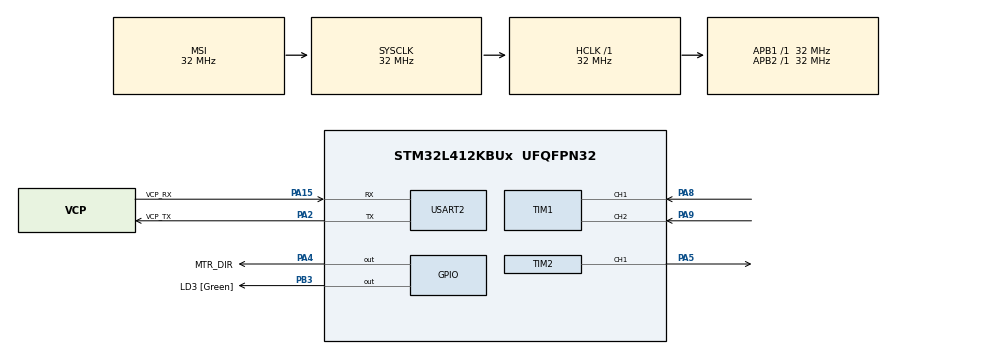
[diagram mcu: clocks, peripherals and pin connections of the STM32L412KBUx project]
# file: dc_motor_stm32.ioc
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Mcu.Family=STM32L4
Mcu.Name=STM32L412KBUx
Mcu.Package=UFQFPN32
NVIC.PriorityGroup=NVIC_PRIORITYGROUP_4
NVIC.TIM1_CC_IRQn=true\:0\:0\:false\:false\:true\:true\:true\:true
PA0-CK_IN.Mode=HSE-External-Clock-Source-for-LittleOrca
PA0-CK_IN.Signal=RCC_CK_IN
PA13\ (JTMS/SWDIO).GPIO_Label=SWDIO
PA13\ (JTMS/SWDIO).Mode=Serial_Wire
PA13\ (JTMS/SWDIO).Signal=SYS_JTMS-SWDIO
PA14\ (JTCK/SWCLK).GPIO_Label=SWCLK
PA14\ (JTCK/SWCLK).Mode=Serial_Wire
PA14\ (JTCK/SWCLK).Signal=SYS_JTCK-SWCLK
PA15\ (JTDI).GPIO_Label=VCP_RX
PA15\ (JTDI).Mode=Asynchronous
PA15\ (JTDI).Signal=USART2_RX
PA2.GPIO_Label=VCP_TX
PA2.Mode=Asynchronous
PA2.Signal=USART2_TX
PA4.GPIO_Label=MTR_DIR
PA4.GPIO_PuPd=GPIO_PULLUP
PA4.Signal=GPIO_Output
PA5.GPIO_PuPd=GPIO_PULLUP
PA5.Signal=S_TIM2_CH1
PA8.GPIO_PuPd=GPIO_PULLUP
PA8.Signal=S_TIM1_CH1
PA9.GPIO_PuPd=GPIO_PULLUP
PA9.Signal=S_TIM1_CH2
PB3\ (JTDO/TRACESWO).GPIO_Label=LD3 [Green]
PB3\ (JTDO/TRACESWO).Signal=GPIO_Output
PC14-OSC32_IN\ (PC14).Mode=LSE-External-Oscillator
PC14-OSC32_IN\ (PC14).Signal=RCC_OSC32_IN
PC15-OSC32_OUT\ (PC15).Mode=LSE-External-Oscillator
PC15-OSC32_OUT\ (PC15).Signal=RCC_OSC32_OUT
ProjectManager.HeapSize=0x200
ProjectManager.StackSize=0x400
ProjectManager.TargetToolchain=STM32CubeIDE
RCC.ADCFreq_Value=32000000
RCC.AHBFreq_Value=32000000
RCC.APB1Freq_Value=32000000
RCC.APB1TimFreq_Value=32000000
RCC.APB2Freq_Value=32000000
RCC.APB2TimFreq_Value=32000000
RCC.CortexFreq_Value=32000000
RCC.FLatency=FLASH_LATENCY_1
RCC.HCLKFreq_Value=32000000
RCC.HSE_VALUE=8000000
RCC.HSI48_VALUE=48000000
RCC.HSICalibrationValue=64
RCC.HSI_VALUE=16000000
RCC.LSE_Drive_Capability=RCC_LSEDRIVE_LOW
RCC.MSIClockRange=RCC_MSIRANGE_10
RCC.MSI_VALUE=32000000
RCC.SYSCLKFreq_VALUE=32000000
RCC.USBFreq_Value=32000000
RCC.VCOOutputFreq_Value=256000000
SH.S_TIM1_CH1.0=TIM1_CH1,Encoder_Interface
SH.S_TIM1_CH2.0=TIM1_CH2,Encoder_Interface
SH.S_TIM2_CH1.0=TIM2_CH1,PWM Generation1 CH1
TIM1.AutoReloadPreload=TIM_AUTORELOAD_PRELOAD_DISABLE
TIM1.EncoderMode=TIM_ENCODERMODE_TI1
TIM2.AutoReloadPreload=TIM_AUTORELOAD_PRELOAD_ENABLE
TIM2.Channel-PWM\ Generation1\ CH1=TIM_CHANNEL_1
USART2.VirtualMode-Asynchronous=VM_ASYNC
board=NUCLEO-L412KB

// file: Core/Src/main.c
/* USER CODE BEGIN Header */
/**
  ******************************************************************************
  * @file           : main.c
  * @brief          : Main program body
  ******************************************************************************
  * @attention
  *
  * Copyright (c) 2024 STMicroelectronics.
  * All rights reserved.
  *
  * This software is licensed under terms that can be found in the LICENSE file
  * in the root directory of this software component.
  * If no LICENSE file comes with this software, it is provided AS-IS.
  *
  ******************************************************************************
  */
/* USER CODE END Header */
#include "main.h"

/* USER CODE BEGIN Includes */
#include "dc_motor.h"
#include "quadrature_encoder_stm32.h"
/* USER CODE END Includes */

TIM_HandleTypeDef htim1;
TIM_HandleTypeDef htim2;

UART_HandleTypeDef huart2;

void SystemClock_Config(void);
static void MX_GPIO_Init(void);
static void MX_USART2_UART_Init(void);
static void MX_TIM1_Init(void);
static void MX_TIM2_Init(void);

int main(void)
{

  /* MCU Configuration--------------------------------------------------------*/

  /* Reset of all peripherals, Initializes the Flash interface and the Systick. */
  HAL_Init();

  /* Configure the system clock */
  SystemClock_Config();

  /* Initialize all configured peripherals */
  MX_GPIO_Init();
  MX_USART2_UART_Init();
  MX_TIM1_Init();
  MX_TIM2_Init();

  /* Infinite loop */
  while (1)
  {

  }
}

void SystemClock_Config(void)
{
  RCC_OscInitTypeDef RCC_OscInitStruct = {0};
  RCC_ClkInitTypeDef RCC_ClkInitStruct = {0};

  /** Configure the main internal regulator output voltage
  */
  if (HAL_PWREx_ControlVoltageScaling(PWR_REGULATOR_VOLTAGE_SCALE1) != HAL_OK)
  {
    Error_Handler();
  }

  /** Configure LSE Drive Capability
  */
  HAL_PWR_EnableBkUpAccess();
  __HAL_RCC_LSEDRIVE_CONFIG(RCC_LSEDRIVE_LOW);

  /** Initializes the RCC Oscillators according to the specified parameters
  * in the RCC_OscInitTypeDef structure.
  */
  RCC_OscInitStruct.OscillatorType = RCC_OSCILLATORTYPE_LSE|RCC_OSCILLATORTYPE_MSI;
  RCC_OscInitStruct.LSEState = RCC_LSE_ON;
  RCC_OscInitStruct.MSIState = RCC_MSI_ON;
  RCC_OscInitStruct.MSICalibrationValue = 0;
  RCC_OscInitStruct.MSIClockRange = RCC_MSIRANGE_10;
  RCC_OscInitStruct.PLL.PLLState = RCC_PLL_NONE;
  if (HAL_RCC_OscConfig(&RCC_OscInitStruct) != HAL_OK)
  {
    Error_Handler();
  }

  /** Initializes the CPU, AHB and APB buses clocks
  */
  RCC_ClkInitStruct.ClockType = RCC_CLOCKTYPE_HCLK|RCC_CLOCKTYPE_SYSCLK
                              |RCC_CLOCKTYPE_PCLK1|RCC_CLOCKTYPE_PCLK2;
  RCC_ClkInitStruct.SYSCLKSource = RCC_SYSCLKSOURCE_MSI;
  RCC_ClkInitStruct.AHBCLKDivider = RCC_SYSCLK_DIV1;
  RCC_ClkInitStruct.APB1CLKDivider = RCC_HCLK_DIV1;
  RCC_ClkInitStruct.APB2CLKDivider = RCC_HCLK_DIV1;

  if (HAL_RCC_ClockConfig(&RCC_ClkInitStruct, FLASH_LATENCY_1) != HAL_OK)
  {
    Error_Handler();
  }

  /** Enable MSI Auto calibration
  */
  HAL_RCCEx_EnableMSIPLLMode();
}

static void MX_TIM1_Init(void)
{

  TIM_Encoder_InitTypeDef sConfig = {0};
  TIM_MasterConfigTypeDef sMasterConfig = {0};

  htim1.Instance = TIM1;
  htim1.Init.Prescaler = 0;
  htim1.Init.CounterMode = TIM_COUNTERMODE_UP;
  htim1.Init.Period = 65535;
  htim1.Init.ClockDivision = TIM_CLOCKDIVISION_DIV1;
  htim1.Init.RepetitionCounter = 0;
  htim1.Init.AutoReloadPreload = TIM_AUTORELOAD_PRELOAD_DISABLE;
  sConfig.EncoderMode = TIM_ENCODERMODE_TI1;
  sConfig.IC1Polarity = TIM_ICPOLARITY_RISING;
  sConfig.IC1Selection = TIM_ICSELECTION_DIRECTTI;
  sConfig.IC1Prescaler = TIM_ICPSC_DIV1;
  sConfig.IC1Filter = 0;
  sConfig.IC2Polarity = TIM_ICPOLARITY_RISING;
  sConfig.IC2Selection = TIM_ICSELECTION_DIRECTTI;
  sConfig.IC2Prescaler = TIM_ICPSC_DIV1;
  sConfig.IC2Filter = 0;
  if (HAL_TIM_Encoder_Init(&htim1, &sConfig) != HAL_OK)
  {
    Error_Handler();
  }
  sMasterConfig.MasterOutputTrigger = TIM_TRGO_RESET;
  sMasterConfig.MasterOutputTrigger2 = TIM_TRGO2_RESET;
  sMasterConfig.MasterSlaveMode = TIM_MASTERSLAVEMODE_DISABLE;
  if (HAL_TIMEx_MasterConfigSynchronization(&htim1, &sMasterConfig) != HAL_OK)
  {
    Error_Handler();
  }

}

static void MX_TIM2_Init(void)
{

  TIM_MasterConfigTypeDef sMasterConfig = {0};
  TIM_OC_InitTypeDef sConfigOC = {0};

  htim2.Instance = TIM2;
  htim2.Init.Prescaler = 0;
  htim2.Init.CounterMode = TIM_COUNTERMODE_UP;
  htim2.Init.Period = 4294967295;
  htim2.Init.ClockDivision = TIM_CLOCKDIVISION_DIV1;
  htim2.Init.AutoReloadPreload = TIM_AUTORELOAD_PRELOAD_ENABLE;
  if (HAL_TIM_PWM_Init(&htim2) != HAL_OK)
  {
    Error_Handler();
  }
  sMasterConfig.MasterOutputTrigger = TIM_TRGO_RESET;
  sMasterConfig.MasterSlaveMode = TIM_MASTERSLAVEMODE_DISABLE;
  if (HAL_TIMEx_MasterConfigSynchronization(&htim2, &sMasterConfig) != HAL_OK)
  {
    Error_Handler();
  }
  sConfigOC.OCMode = TIM_OCMODE_PWM1;
  sConfigOC.Pulse = 0;
  sConfigOC.OCPolarity = TIM_OCPOLARITY_HIGH;
  sConfigOC.OCFastMode = TIM_OCFAST_DISABLE;
  if (HAL_TIM_PWM_ConfigChannel(&htim2, &sConfigOC, TIM_CHANNEL_1) != HAL_OK)
  {
    Error_Handler();
  }
  HAL_TIM_MspPostInit(&htim2);

}

static void MX_USART2_UART_Init(void)
{

  huart2.Instance = USART2;
  huart2.Init.BaudRate = 115200;
  huart2.Init.WordLength = UART_WORDLENGTH_8B;
  huart2.Init.StopBits = UART_STOPBITS_1;
  huart2.Init.Parity = UART_PARITY_NONE;
  huart2.Init.Mode = UART_MODE_TX_RX;
  huart2.Init.HwFlowCtl = UART_HWCONTROL_NONE;
  huart2.Init.OverSampling = UART_OVERSAMPLING_16;
  huart2.Init.OneBitSampling = UART_ONE_BIT_SAMPLE_DISABLE;
  huart2.AdvancedInit.AdvFeatureInit = UART_ADVFEATURE_NO_INIT;
  if (HAL_UART_Init(&huart2) != HAL_OK)
  {
    Error_Handler();
  }

}

static void MX_GPIO_Init(void)
{
  GPIO_InitTypeDef GPIO_InitStruct = {0};

  /* GPIO Ports Clock Enable */
  __HAL_RCC_GPIOC_CLK_ENABLE();
  __HAL_RCC_GPIOA_CLK_ENABLE();
  __HAL_RCC_GPIOB_CLK_ENABLE();

  /*Configure GPIO pin Output Level */
  HAL_GPIO_WritePin(MTR_DIR_GPIO_Port, MTR_DIR_Pin, GPIO_PIN_RESET);

  /*Configure GPIO pin Output Level */
  HAL_GPIO_WritePin(LD3_GPIO_Port, LD3_Pin, GPIO_PIN_RESET);

  /*Configure GPIO pin : MTR_DIR_Pin */
  GPIO_InitStruct.Pin = MTR_DIR_Pin;
  GPIO_InitStruct.Mode = GPIO_MODE_OUTPUT_PP;
  GPIO_InitStruct.Pull = GPIO_PULLUP;
  GPIO_InitStruct.Speed = GPIO_SPEED_FREQ_LOW;
  HAL_GPIO_Init(MTR_DIR_GPIO_Port, &GPIO_InitStruct);

  /*Configure GPIO pin : LD3_Pin */
  GPIO_InitStruct.Pin = LD3_Pin;
  GPIO_InitStruct.Mode = GPIO_MODE_OUTPUT_PP;
  GPIO_InitStruct.Pull = GPIO_NOPULL;
  GPIO_InitStruct.Speed = GPIO_SPEED_FREQ_LOW;
  HAL_GPIO_Init(LD3_GPIO_Port, &GPIO_InitStruct);

}

void Error_Handler(void)
{
  __disable_irq();
  while (1)
  {
  }
}
